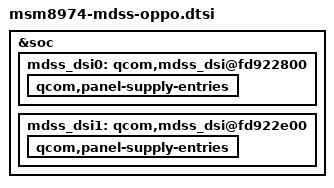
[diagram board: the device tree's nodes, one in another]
/* Copyright (c) 2012-2014, The Linux Foundation. All rights reserved.
 *
 * This program is free software; you can redistribute it and/or modify
 * it under the terms of the GNU General Public License version 2 and
 * only version 2 as published by the Free Software Foundation.
 *
 * This program is distributed in the hope that it will be useful,
 * but WITHOUT ANY WARRANTY; without even the implied warranty of
 * MERCHANTABILITY or FITNESS FOR A PARTICULAR PURPOSE.  See the
 * GNU General Public License for more details.
 */

&soc {
	mdss_dsi0: qcom,mdss_dsi@fd922800 {
		/delete-property/ vdd-supply;

		qcom,panel-supply-entries {
			/delete-node/ qcom,panel-supply-entry@0;
		};
	};

	mdss_dsi1: qcom,mdss_dsi@fd922e00 {
		/delete-property/ vdd-supply;

		qcom,panel-supply-entries {
			/delete-node/ qcom,panel-supply-entry@0;
		};
	};
};
